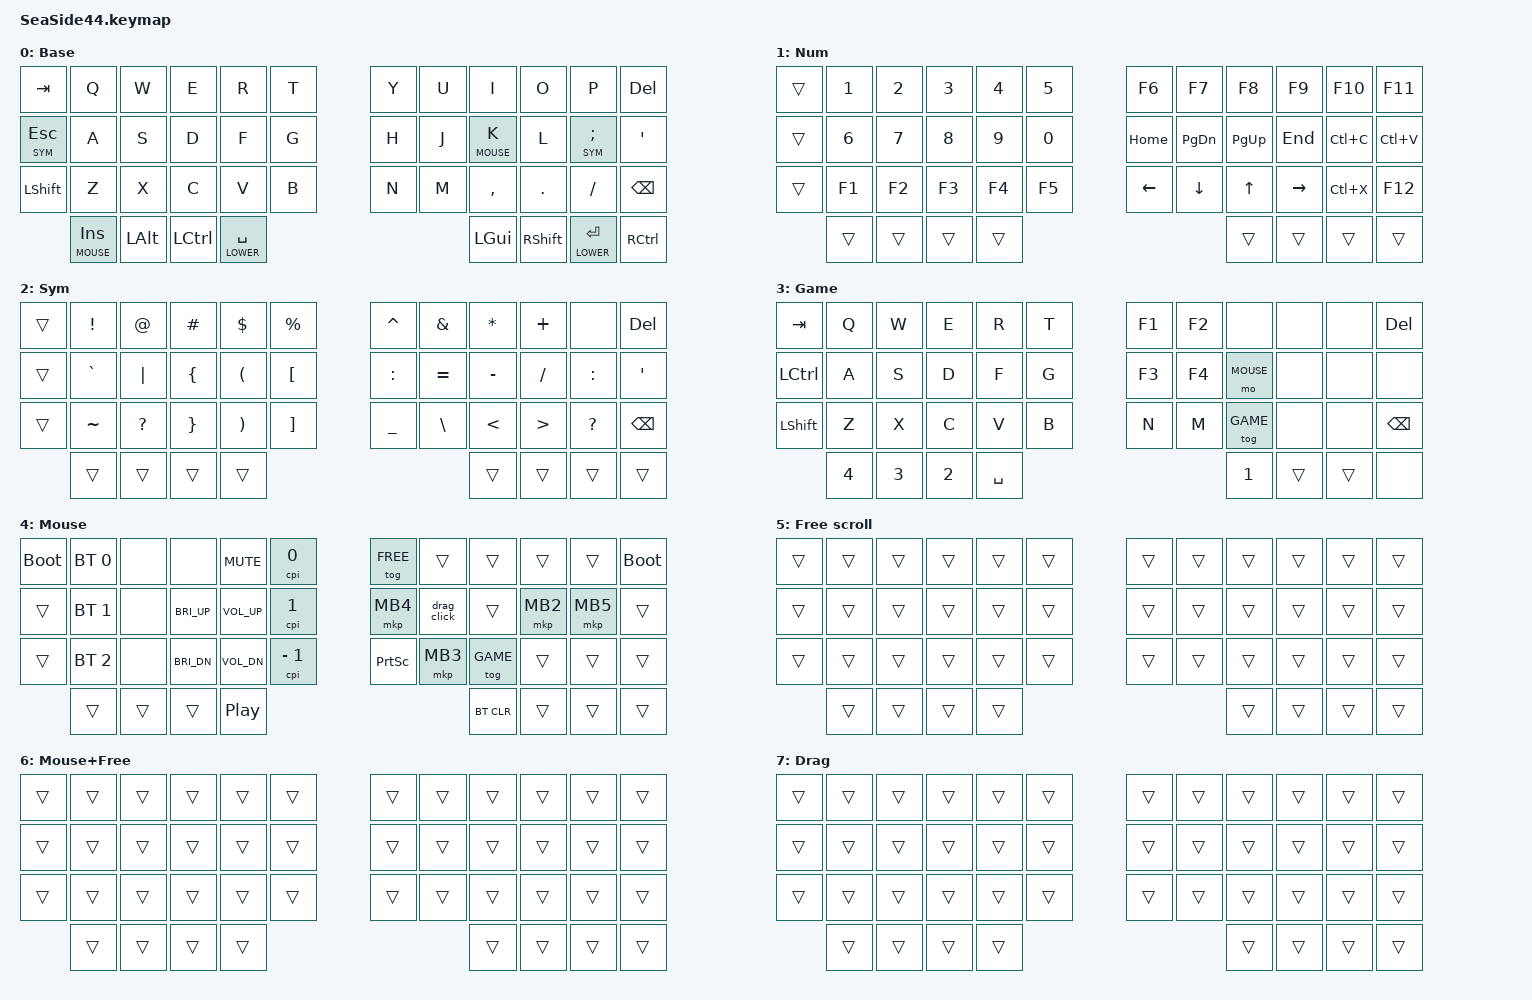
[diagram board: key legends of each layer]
#include <behaviors.dtsi>
#include <dt-bindings/zmk/bt.h>
#include <dt-bindings/zmk/keys.h>
#include <dt-bindings/zmk/pointing.h>

#define BASE 0
#define LOWER 1
#define SYM 2
#define GAME 3
#define MOUSE 4
#define FREE 5
#define MOUSE_FREE 6
#define DRAG 7

&mt {
    flavor = "tap-preferred";
    tapping-term-ms = <150>;
    quick-tap-ms = <150>;
};

&lt {
    flavor = "tap-preferred";
    tapping-term-ms = <150>;
    quick-tap-ms = <150>;
};

/ {
    macros {
        drag_click: drag_click {
            compatible = "zmk,behavior-macro";
            label = "DRAG_CLICK";
            #binding-cells = <0>;
            wait-ms = <0>;
            tap-ms = <0>;
            bindings
                = <&macro_press &mo DRAG &mkp LCLK>
                , <&macro_pause_for_release>
                , <&macro_release &mkp LCLK &mo DRAG>
                ;
        };
    };

    behaviors {
        mouse_k: mouse_k {
            compatible = "zmk,behavior-hold-tap";
            label = "MOUSE_K";
            #binding-cells = <2>;
            bindings = <&mo>, <&kp>;
            flavor = "balanced";
            tapping-term-ms = <200>;
            quick-tap-ms = <150>;
            hold-while-undecided;
        };

        swapper: swapper {
            compatible = "zmk,behavior-smart-toggle";
            label = "SWAPPER";
            #binding-cells = <0>;
            bindings = <&kp LALT>, <&kp TAB>;
            ignored-key-positions = <26 27 28>;
        };

        swapper_back: swapper_back {
            compatible = "zmk,behavior-smart-toggle";
            label = "SWAPPER_BACK";
            #binding-cells = <0>;
            bindings = <&kp LALT>, <&kp LS(TAB)>;
            ignored-key-positions = <26 27 28>;
        };
    };

    conditional_layers {
        compatible = "zmk,conditional-layers";
        mouse_free {
            if-layers = <MOUSE FREE>;
            then-layer = <MOUSE_FREE>;
        };
    };

    combos {
        compatible = "zmk,combos";
        ctrl_tab {
            key-positions = <3 4>;
            bindings = <&kp LC(TAB)>;
            layers = <BASE>;
            timeout-ms = <40>;
            require-prior-idle-ms = <150>;
        };
        ctrl_shift_tab {
            key-positions = <2 3>;
            bindings = <&kp LC(LS(TAB))>;
            layers = <BASE>;
            timeout-ms = <40>;
            require-prior-idle-ms = <150>;
        };
        alt_tab {
            key-positions = <27 28>;
            bindings = <&swapper>;
            layers = <BASE>;
            timeout-ms = <40>;
            require-prior-idle-ms = <150>;
        };
        alt_shift_tab {
            key-positions = <26 27>;
            bindings = <&swapper_back>;
            layers = <BASE>;
            timeout-ms = <40>;
            require-prior-idle-ms = <150>;
        };
        ctrl_b {
            key-positions = <28 29>;
            bindings = <&kp LC(B)>;
            layers = <BASE>;
            timeout-ms = <40>;
            require-prior-idle-ms = <150>;
        };
        alt_f4 {
            key-positions = <28 29>;
            bindings = <&kp LA(F4)>;
            layers = <LOWER>;
        };
        game_esc {
            key-positions = <0 1>;
            bindings = <&kp ESC>;
            layers = <GAME>;
        };
        game_m {
            key-positions = <25 16>;
            bindings = <&kp M>;
            layers = <GAME>;
        };
        game_f1 {
            key-positions = <25 40>;
            bindings = <&kp F1>;
            layers = <GAME>;
        };
        game_f2 {
            key-positions = <25 38>;
            bindings = <&kp F2>;
            layers = <GAME>;
        };
        game_f3 {
            key-positions = <25 37>;
            bindings = <&kp F3>;
            layers = <GAME>;
        };
        game_f4 {
            key-positions = <25 36>;
            bindings = <&kp F4>;
            layers = <GAME>;
        };
    };

    keymap {
        compatible = "zmk,keymap";

        default_layer {
            display-name = "Base";
            bindings = <
&kp TAB             &kp Q     &kp W     &kp E      &kp R          &kp T                    &kp Y      &kp U       &kp I        &kp O    &kp P           &kp DEL
&lt SYM ESC         &kp A     &kp S     &kp D      &kp F          &kp G                    &kp H      &kp J       &mouse_k MOUSE K &kp L    &lt SYM SEMI    &kp SQT
&kp LSHFT           &kp Z     &kp X     &kp C      &kp V          &kp B                    &kp N      &kp M       &kp COMMA    &kp DOT  &kp FSLH        &kp BSPC
                    &lt MOUSE INS  &kp LALT  &kp LCTRL  &lt LOWER SPACE  &kp LGUI     &kp RSHFT  &lt LOWER RET                                   &kp RCTRL
            >;
        };

        lower_layer {
            display-name = "Num";
            bindings = <
&trans  &kp N1  &kp N2  &kp N3  &kp N4  &kp N5             &kp F6    &kp F7    &kp F8    &kp F9     &kp F10    &kp F11
&trans  &kp N6  &kp N7  &kp N8  &kp N9  &kp N0             &kp HOME  &kp PG_DN &kp PG_UP &kp END    &kp LC(C)  &kp LC(V)
&trans  &kp F1  &kp F2  &kp F3  &kp F4  &kp F5             &kp LEFT  &kp DOWN  &kp UP    &kp RIGHT  &kp LC(X)  &kp F12
                &trans  &trans  &trans  &trans  &trans     &trans    &trans                                    &trans
            >;
        };

        symbol_layer {
            display-name = "Sym";
            bindings = <
&trans  &kp EXCL   &kp AT     &kp HASH  &kp DLLR  &kp PRCNT        &kp CARET  &kp AMPS  &kp STAR  &kp PLUS  &none      &kp DEL
&trans  &kp GRAVE  &kp PIPE   &kp LBRC  &kp LPAR  &kp LBKT         &kp COLON  &kp EQUAL &kp MINUS &kp FSLH  &kp COLON  &kp SQT
&trans  &kp TILDE  &kp QMARK  &kp RBRC  &kp RPAR  &kp RBKT         &kp UNDER  &kp BSLH  &kp LT    &kp GT    &kp QMARK  &kp BSPC
                   &trans     &trans    &trans    &trans  &trans   &trans     &trans                                   &trans
            >;
        };

        game_layer {
            display-name = "Game";
            bindings = <
&kp TAB    &kp Q   &kp W   &kp E   &kp R          &kp T              &kp F1  &kp F2  &none      &none  &none  &kp DEL
&kp LCTRL  &kp A   &kp S   &kp D   &kp F          &kp G              &kp F3  &kp F4  &mo MOUSE  &none  &none  &none
&kp LSHFT  &kp Z   &kp X   &kp C   &kp V          &kp B             &kp N   &kp M   &tog GAME  &none  &none  &kp BSPC
                   &kp N4  &kp N3  &kp N2         &kp SPACE  &kp N1  &trans  &trans                             &none
            >;
        };

        mouse_layer {
            display-name = "Mouse";
            bindings = <
&bootloader &bt BT_SEL 0 &none    &none       &kp C_MUTE   &cpi 0          &tog FREE  &trans    &trans     &trans    &trans    &bootloader
&trans  &bt BT_SEL 1  &none        &kp C_BRI_UP &kp C_VOL_UP &cpi 1      &mkp MB4   &drag_click &trans   &mkp MB2  &mkp MB5  &trans
&trans     &bt BT_SEL 2 &none     &kp C_BRI_DN &kp C_VOL_DN &cpi (-1)                &kp PSCRN  &mkp MB3  &tog GAME  &trans    &trans    &trans
                      &trans       &trans      &trans  &kp C_PLAY_PAUSE  &bt BT_CLR  &trans      &trans                                     &trans
            >;
        };

        free_layer {
            display-name = "Free scroll";
            bindings = <
&trans  &trans  &trans  &trans  &trans  &trans             &trans  &trans  &trans  &trans  &trans  &trans
&trans  &trans  &trans  &trans  &trans  &trans             &trans  &trans  &trans  &trans  &trans  &trans
&trans  &trans  &trans  &trans  &trans  &trans             &trans  &trans  &trans  &trans  &trans  &trans
                &trans  &trans  &trans  &trans  &trans     &trans  &trans                          &trans
            >;
        };

        mouse_free_layer {
            display-name = "Mouse+Free";
            bindings = <
&trans  &trans  &trans  &trans  &trans  &trans             &trans  &trans  &trans  &trans  &trans  &trans
&trans  &trans  &trans  &trans  &trans  &trans             &trans  &trans  &trans  &trans  &trans  &trans
&trans  &trans  &trans  &trans  &trans  &trans             &trans  &trans  &trans  &trans  &trans  &trans
                &trans  &trans  &trans  &trans  &trans     &trans  &trans                          &trans
            >;
        };

        drag_layer {
            display-name = "Drag";
            bindings = <
&trans  &trans  &trans  &trans  &trans  &trans             &trans  &trans  &trans  &trans  &trans  &trans
&trans  &trans  &trans  &trans  &trans  &trans             &trans  &trans  &trans  &trans  &trans  &trans
&trans  &trans  &trans  &trans  &trans  &trans             &trans  &trans  &trans  &trans  &trans  &trans
                &trans  &trans  &trans  &trans  &trans     &trans  &trans                          &trans
            >;
        };
    };
};
